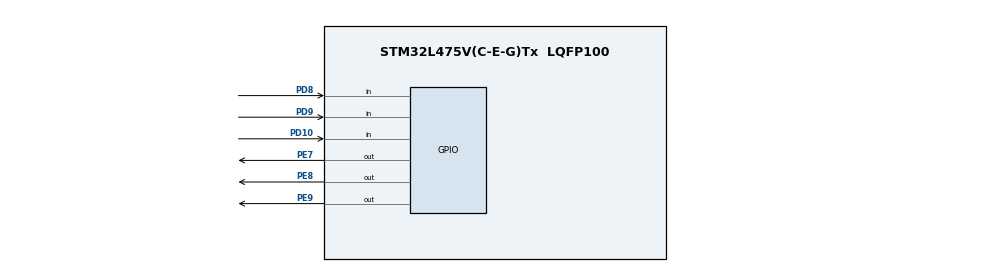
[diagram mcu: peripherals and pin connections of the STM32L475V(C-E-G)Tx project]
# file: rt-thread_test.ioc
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Mcu.Family=STM32L4
Mcu.Name=STM32L475V(C-E-G)Tx
Mcu.Package=LQFP100
NVIC.PriorityGroup=NVIC_PRIORITYGROUP_4
PD10.Signal=GPIO_Input
PD8.Signal=GPIO_Input
PD9.Signal=GPIO_Input
PE7.Signal=GPIO_Output
PE8.Signal=GPIO_Output
PE9.Signal=GPIO_Output
ProjectManager.HeapSize=0x200
ProjectManager.StackSize=0x400
ProjectManager.TargetToolchain=MDK-ARM V5
RCC.HSE_VALUE=8000000
RCC.HSI_VALUE=16000000
RCC.LSE_VALUE=32768
RCC.MSI_VALUE=4000000
RCC.VCOOutputFreq_Value=32000000
VP_rt-thread.rtthread_VS_RTOSJjRTAaThread_3.1.1.Mode=RTOSJjRTAaThread
board=custom
rt-thread.rtthread.3.1.1.RTAaThreadCcRTOSJjkernel=true
rt-thread.rtthread.3.1.1.RTOSJjRTAaThread.cmp_version0=3.1.1
rt-thread.rtthread.3.1.1.RTOSJjRTAaThread.component0=RTOS
rt-thread.rtthread.3.1.1.RTOSJjRTAaThread.description0=rt-thread,rt-thread kernel files
rt-thread.rtthread.3.1.1.RTOSJjRTAaThread.diagnostic0=This component should operate correctly.
rt-thread.rtthread.3.1.1.RTOSJjRTAaThread.group0=kernel
rt-thread.rtthread.3.1.1.RTOSJjRTAaThread.paramName0=RTAaThreadCcRTOSJjkernel
rt-thread.rtthread.3.1.1.RTOSJjRTAaThread.sevirity0=none
rt-thread.rtthread.3.1.1.RTOSJjRTAaThread_bundle=RT-Thread
rt-thread.rtthread.3.1.1.RTOSJjRTAaThread_class=RTOS
rt-thread.rtthread.3.1.1.RTOSJjRTAaThread_name=rtthread
rt-thread.rtthread.3.1.1.RTOSJjRTAaThread_size=1
rt-thread.rtthread.3.1.1.RTOSJjRTAaThread_vendor=rt-thread
rt-thread.rtthread.3.1.1.RTOSJjRTAaThread_version=3.1.1
rt-thread.rtthread.3.1.1_MwName0=RT-Thread
rt-thread.rtthread.3.1.1_NumberOfMw=1
rt-thread.rtthread.3.1.1_RTOSJjRTAaThread_RteComponentsize=0
rt-thread.rtthread.3.1.1_description=RT-Thread Software Components
rt-thread.rtthread.3.1.1_license=License.txt

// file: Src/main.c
/* USER CODE BEGIN Header */
/**
  ******************************************************************************
  * @file           : main.c
  * @brief          : Main program body
  ******************************************************************************
  * This notice applies to any and all portions of this file
  * that are not between comment pairs USER CODE BEGIN and
  * USER CODE END. Other portions of this file, whether
  * inserted by the user or by software development tools
  * are owned by their respective copyright owners.
  *
  * Copyright (c) 2018 STMicroelectronics International N.V.
  * All rights reserved.
  *
  * Redistribution and use in source and binary forms, with or without
  * modification, are permitted, provided that the following conditions are met:
  *
  * 1. Redistribution of source code must retain the above copyright notice,
  *    this list of conditions and the following disclaimer.
  * 2. Redistributions in binary form must reproduce the above copyright notice,
  *    this list of conditions and the following disclaimer in the documentation
  *    and/or other materials provided with the distribution.
  * 3. Neither the name of STMicroelectronics nor the names of other
  *    contributors to this software may be used to endorse or promote products
  *    derived from this software without specific written permission.
  * 4. This software, including modifications and/or derivative works of this
  *    software, must execute solely and exclusively on microcontroller or
  *    microprocessor devices manufactured by or for STMicroelectronics.
  * 5. Redistribution and use of this software other than as permitted under
  *    this license is void and will automatically terminate your rights under
  *    this license.
  *
  * THIS SOFTWARE IS PROVIDED BY STMICROELECTRONICS AND CONTRIBUTORS "AS IS"
  * AND ANY EXPRESS, IMPLIED OR STATUTORY WARRANTIES, INCLUDING, BUT NOT
  * LIMITED TO, THE IMPLIED WARRANTIES OF MERCHANTABILITY, FITNESS FOR A
  * PARTICULAR PURPOSE AND NON-INFRINGEMENT OF THIRD PARTY INTELLECTUAL PROPERTY
  * RIGHTS ARE DISCLAIMED TO THE FULLEST EXTENT PERMITTED BY LAW. IN NO EVENT
  * SHALL STMICROELECTRONICS OR CONTRIBUTORS BE LIABLE FOR ANY DIRECT, INDIRECT,
  * INCIDENTAL, SPECIAL, EXEMPLARY, OR CONSEQUENTIAL DAMAGES (INCLUDING, BUT NOT
  * LIMITED TO, PROCUREMENT OF SUBSTITUTE GOODS OR SERVICES; LOSS OF USE, DATA,
  * OR PROFITS; OR BUSINESS INTERRUPTION) HOWEVER CAUSED AND ON ANY THEORY OF
  * LIABILITY, WHETHER IN CONTRACT, STRICT LIABILITY, OR TORT (INCLUDING
  * NEGLIGENCE OR OTHERWISE) ARISING IN ANY WAY OUT OF THE USE OF THIS SOFTWARE,
  * EVEN IF ADVISED OF THE POSSIBILITY OF SUCH DAMAGE.
  *
  ******************************************************************************
  */
/* USER CODE END Header */

#include "main.h"

/* USER CODE BEGIN PV */
extern void MX_rtthread_Process(void);
/* USER CODE END PV */

void SystemClock_Config(void);
static void MX_GPIO_Init(void);

int main(void)
{

  /* MCU Configuration--------------------------------------------------------*/

  /* Reset of all peripherals, Initializes the Flash interface and the Systick. */
  HAL_Init();

  /* Configure the system clock */
  SystemClock_Config();

  /* Initialize all configured peripherals */
  MX_GPIO_Init();

  /* Infinite loop */
  /* USER CODE BEGIN WHILE */
//  while (1)
  {
    /* USER CODE END WHILE */
    MX_rtthread_Process();
  }
}

void SystemClock_Config(void)
{
  RCC_OscInitTypeDef RCC_OscInitStruct = {0};
  RCC_ClkInitTypeDef RCC_ClkInitStruct = {0};

  /**Initializes the CPU, AHB and APB busses clocks
  */
  RCC_OscInitStruct.OscillatorType = RCC_OSCILLATORTYPE_MSI;
  RCC_OscInitStruct.MSIState = RCC_MSI_ON;
  RCC_OscInitStruct.MSICalibrationValue = 0;
  RCC_OscInitStruct.MSIClockRange = RCC_MSIRANGE_6;
  RCC_OscInitStruct.PLL.PLLState = RCC_PLL_NONE;
  if (HAL_RCC_OscConfig(&RCC_OscInitStruct) != HAL_OK)
  {
    Error_Handler();
  }
  /**Initializes the CPU, AHB and APB busses clocks
  */
  RCC_ClkInitStruct.ClockType = RCC_CLOCKTYPE_HCLK|RCC_CLOCKTYPE_SYSCLK
                              |RCC_CLOCKTYPE_PCLK1|RCC_CLOCKTYPE_PCLK2;
  RCC_ClkInitStruct.SYSCLKSource = RCC_SYSCLKSOURCE_MSI;
  RCC_ClkInitStruct.AHBCLKDivider = RCC_SYSCLK_DIV1;
  RCC_ClkInitStruct.APB1CLKDivider = RCC_HCLK_DIV1;
  RCC_ClkInitStruct.APB2CLKDivider = RCC_HCLK_DIV1;

  if (HAL_RCC_ClockConfig(&RCC_ClkInitStruct, FLASH_LATENCY_0) != HAL_OK)
  {
    Error_Handler();
  }
  /**Configure the main internal regulator output voltage
  */
  if (HAL_PWREx_ControlVoltageScaling(PWR_REGULATOR_VOLTAGE_SCALE1) != HAL_OK)
  {
    Error_Handler();
  }
}

static void MX_GPIO_Init(void)
{
  GPIO_InitTypeDef GPIO_InitStruct = {0};

  /* GPIO Ports Clock Enable */
  __HAL_RCC_GPIOE_CLK_ENABLE();
  __HAL_RCC_GPIOD_CLK_ENABLE();

  /*Configure GPIO pin Output Level */
  HAL_GPIO_WritePin(GPIOE, GPIO_PIN_7|GPIO_PIN_8|GPIO_PIN_9, GPIO_PIN_RESET);

  /*Configure GPIO pins : PE7 PE8 PE9 */
  GPIO_InitStruct.Pin = GPIO_PIN_7|GPIO_PIN_8|GPIO_PIN_9;
  GPIO_InitStruct.Mode = GPIO_MODE_OUTPUT_PP;
  GPIO_InitStruct.Pull = GPIO_NOPULL;
  GPIO_InitStruct.Speed = GPIO_SPEED_FREQ_LOW;
  HAL_GPIO_Init(GPIOE, &GPIO_InitStruct);

  /*Configure GPIO pins : PD8 PD9 PD10 */
  GPIO_InitStruct.Pin = GPIO_PIN_8|GPIO_PIN_9|GPIO_PIN_10;
  GPIO_InitStruct.Mode = GPIO_MODE_INPUT;
  GPIO_InitStruct.Pull = GPIO_NOPULL;
  HAL_GPIO_Init(GPIOD, &GPIO_InitStruct);

}

void Error_Handler(void)
{
}

/************************ (C) COPYRIGHT STMicroelectronics *****END OF FILE****/
